# ioat91sam3s2 register map
Registers are 32-bit, access not given, no defined reset value unless marked. A register's access mark holds for its fields unless they carry their own. Addresses are absolute; registers are grouped by the start of their names; [hi:lo] are bit positions; {n}, {i} and the like mark numbered series; 'fields as' and 'values as' point back to an identical list.

## ACC
0x40040000 ACC_CR
  [0] SWRST
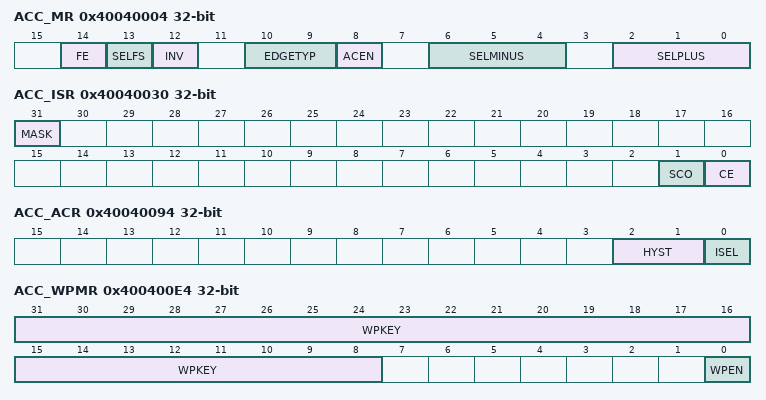
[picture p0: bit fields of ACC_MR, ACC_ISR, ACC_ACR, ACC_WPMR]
0x40040004 ACC_MR
  [14] FE, [13] SELFS, [12] INV, [10:9] EDGETYP, [8] ACEN, [6:4] SELMINUS, [2:0] SELPLUS
0x40040024 ACC_IER
  [0] CE
0x40040028 ACC_IDR
  [0] CE
0x4004002C ACC_IMR
  [0] CE
0x40040030 ACC_ISR
  [31] MASK, [1] SCO, [0] CE
0x40040094 ACC_ACR
  [2:1] HYST, [0] ISEL
0x400400E4 ACC_WPMR
  [31:8] WPKEY, [0] WPEN
0x400400E8 ACC_WPSR
  [0] WPROTERR

## CRCCU
0x40044000 CRCCU_DSCR
  [31:9] DSCR
0x40044008 CRCCU_DMA_EN
  [0] DMAEN
0x4004400C CRCCU_DMA_DIS
  [0] DMADIS
0x40044010 CRCCU_DMA_SR
  [0] DMASR
0x40044014 CRCCU_DMA_IER
  [0] DMAIER
0x40044018 CRCCU_DMA_IDR
  [0] DMAIDR
0x4004401C CRCCU_DMA_IMR
  [0] DMAIMR
0x40044020 CRCCU_DMA_ISR
  [0] DMAISR
0x40044034 CRCCU_CR
  [0] RESET
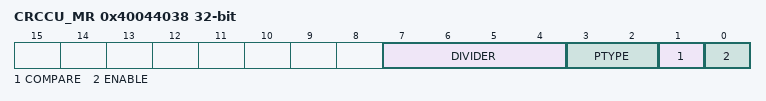
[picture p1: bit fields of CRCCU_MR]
0x40044038 CRCCU_MR
  [7:4] DIVIDER, [3:2] PTYPE, [1] COMPARE, [0] ENABLE
0x4004403C CRCCU_SR
  [31:0] CRC
0x40044040 CRCCU_IER
  [0] ERRIER
0x40044044 CRCCU_IDR
  [0] ERRIDR
0x40044048 CRCCU_IMR
  [0] ERRIMR
0x4004404C CRCCU_ISR
  [0] ERRISR

## SMC
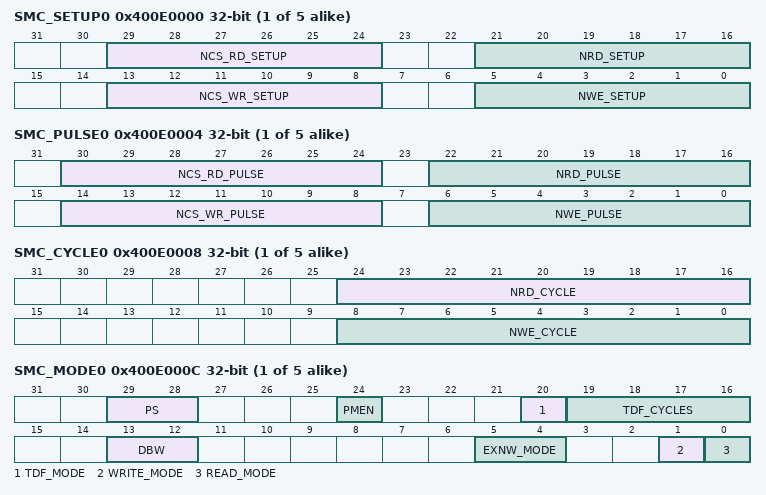
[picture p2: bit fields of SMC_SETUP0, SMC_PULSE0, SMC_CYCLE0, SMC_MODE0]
{0x400E0000+0x10*i} SMC_SETUP{i} (i=0..4)
  [29:24] NCS_RD_SETUP, [21:16] NRD_SETUP, [13:8] NCS_WR_SETUP, [5:0] NWE_SETUP
{0x400E0004+0x10*i} SMC_PULSE{i} (i=0..4)
  [30:24] NCS_RD_PULSE, [22:16] NRD_PULSE, [14:8] NCS_WR_PULSE, [6:0] NWE_PULSE
{0x400E0008+0x10*i} SMC_CYCLE{i} (i=0..4)
  [24:16] NRD_CYCLE, [8:0] NWE_CYCLE
{0x400E000C+0x10*i} SMC_MODE{i} (i=0..4)
  [29:28] PS, [24] PMEN, [20] TDF_MODE, [19:16] TDF_CYCLES, [13:12] DBW, [5:4] EXNW_MODE, [1] WRITE_MODE, [0] READ_MODE
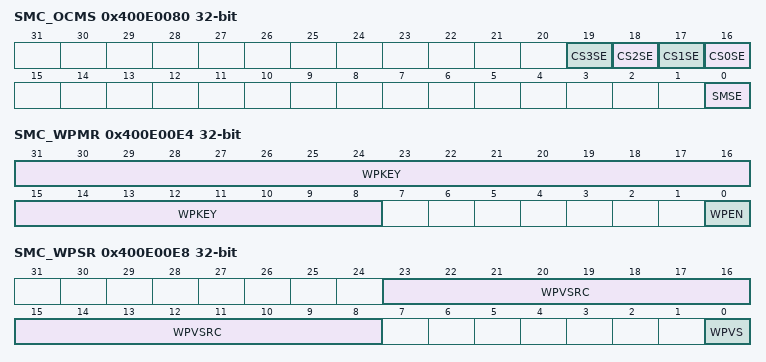
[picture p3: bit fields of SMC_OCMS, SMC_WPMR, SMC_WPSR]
0x400E0080 SMC_OCMS
  [n+16] CS{n}SE (n=0..3), [0] SMSE
0x400E0084 SMC_KEY1
0x400E0088 SMC_KEY2
0x400E00E4 SMC_WPMR
  [31:8] WPKEY, [0] WPEN
0x400E00E8 SMC_WPSR
  [23:8] WPVSRC, [0] WPVS

## MATRIX
0x400E0200 MATRIX_MCFG_{i} (i=0..3)
  [2:0] ULBT
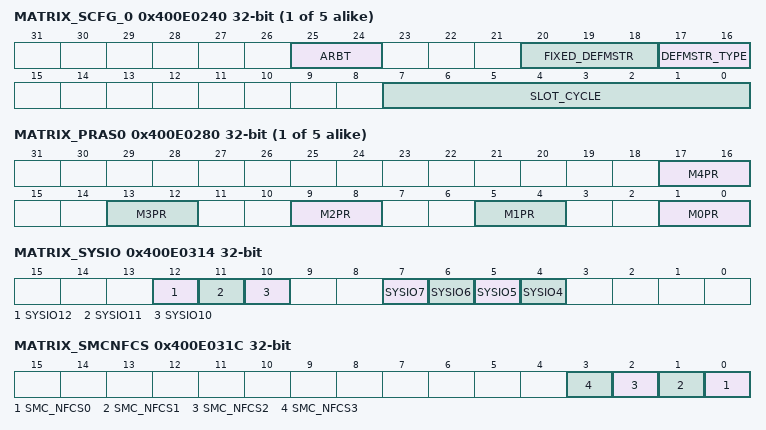
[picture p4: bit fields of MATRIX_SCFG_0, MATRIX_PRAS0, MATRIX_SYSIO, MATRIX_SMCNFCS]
0x400E0240 MATRIX_SCFG_{i} (i=0..4)
  [25:24] ARBT, [20:18] FIXED_DEFMSTR, [17:16] DEFMSTR_TYPE, [7:0] SLOT_CYCLE
{0x400E0280+8i} MATRIX_PRAS{i} (i=0..4)
  [4n+1:4n] M{n}PR (n=0..4)
0x400E0314 MATRIX_SYSIO
  [12] SYSIO12, [11] SYSIO11, [10] SYSIO10, [n] SYSIO{n} (n=4..7)
0x400E031C MATRIX_SMCNFCS
  [n] SMC_NFCS{n} (n=0..3)
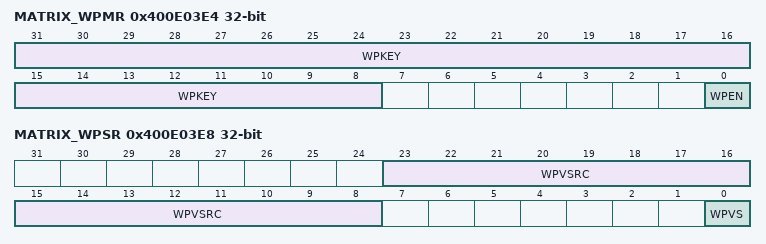
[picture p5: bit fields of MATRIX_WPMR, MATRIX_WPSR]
0x400E03E4 MATRIX_WPMR
  [31:8] WPKEY, [0] WPEN
0x400E03E8 MATRIX_WPSR
  [23:8] WPVSRC, [0] WPVS

## PMC
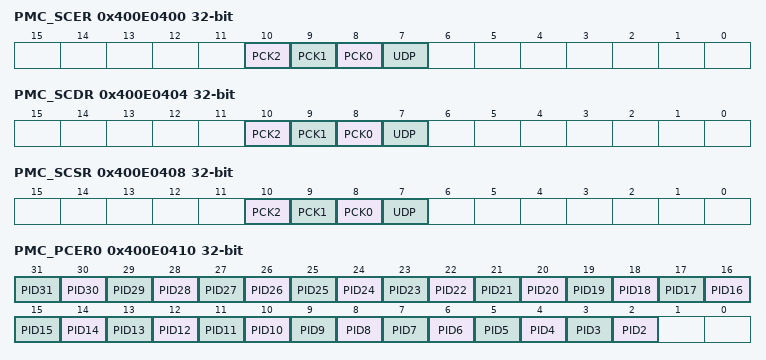
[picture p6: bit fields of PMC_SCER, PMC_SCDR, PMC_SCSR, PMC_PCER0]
0x400E0400 PMC_SCER
  [10] PCK2, [9] PCK1, [8] PCK0, [7] UDP
0x400E0404 PMC_SCDR
  [10] PCK2, [9] PCK1, [8] PCK0, [7] UDP
0x400E0408 PMC_SCSR
  [10] PCK2, [9] PCK1, [8] PCK0, [7] UDP
0x400E0410 PMC_PCER0
  [n] PID{n} (n=2..31)
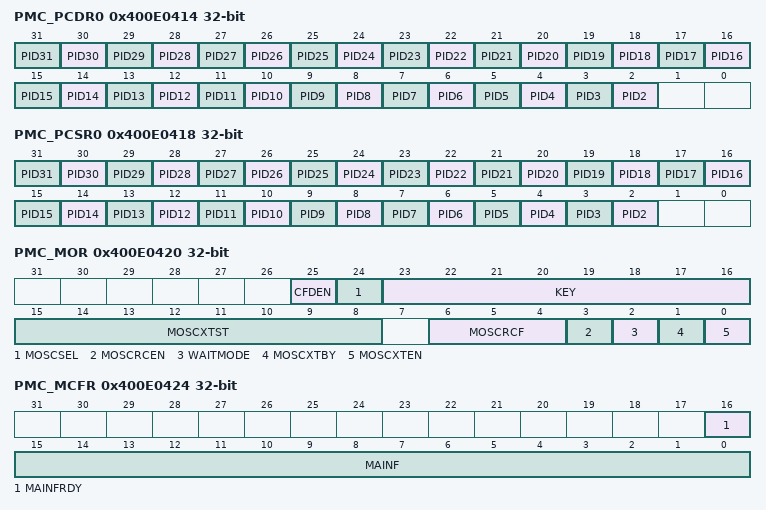
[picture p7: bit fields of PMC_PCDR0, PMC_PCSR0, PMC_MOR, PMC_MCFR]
0x400E0414 PMC_PCDR0
  [n] PID{n} (n=2..31)
0x400E0418 PMC_PCSR0
  [n] PID{n} (n=2..31)
0x400E0420 PMC_MOR
  [25] CFDEN, [24] MOSCSEL, [23:16] KEY, [15:8] MOSCXTST, [6:4] MOSCRCF, [3] MOSCRCEN, [2] WAITMODE, [1] MOSCXTBY, [0] MOSCXTEN
0x400E0424 PMC_MCFR
  [16] MAINFRDY, [15:0] MAINF
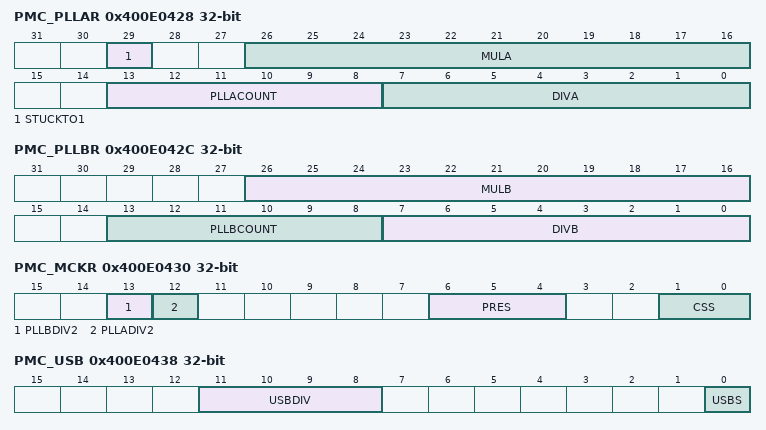
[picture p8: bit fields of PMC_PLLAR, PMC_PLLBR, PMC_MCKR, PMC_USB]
0x400E0428 PMC_PLLAR
  [29] STUCKTO1, [26:16] MULA, [13:8] PLLACOUNT, [7:0] DIVA
0x400E042C PMC_PLLBR
  [26:16] MULB, [13:8] PLLBCOUNT, [7:0] DIVB
0x400E0430 PMC_MCKR
  [13] PLLBDIV2, [12] PLLADIV2, [6:4] PRES, [1:0] CSS
0x400E0438 PMC_USB
  [11:8] USBDIV, [0] USBS
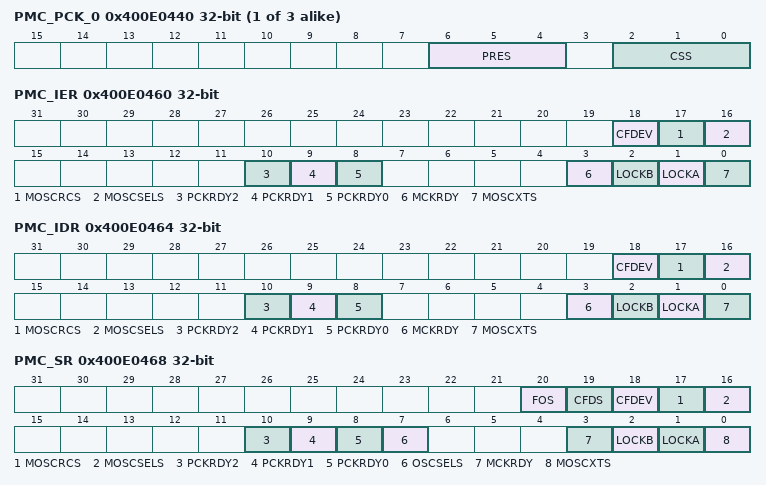
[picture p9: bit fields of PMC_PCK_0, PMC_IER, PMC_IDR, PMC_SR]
0x400E0440 PMC_PCK_{i} (i=0..2)
  [6:4] PRES, [2:0] CSS
0x400E0460 PMC_IER
  [18] CFDEV, [17] MOSCRCS, [16] MOSCSELS, [10] PCKRDY2, [9] PCKRDY1, [8] PCKRDY0, [3] MCKRDY, [2] LOCKB, [1] LOCKA, [0] MOSCXTS
0x400E0464 PMC_IDR
  fields as PMC_IER
0x400E0468 PMC_SR
  [20] FOS, [19] CFDS, [18] CFDEV, [17] MOSCRCS, [16] MOSCSELS, [10] PCKRDY2, [9] PCKRDY1, [8] PCKRDY0, [7] OSCSELS, [3] MCKRDY, [2] LOCKB, [1] LOCKA, [0] MOSCXTS
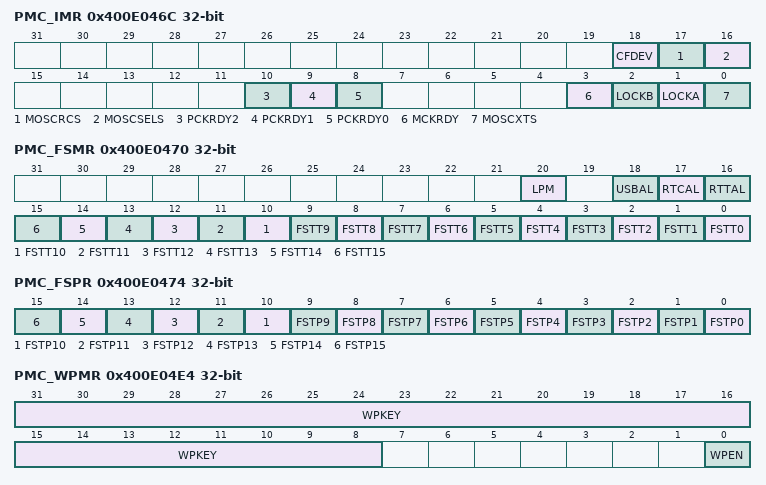
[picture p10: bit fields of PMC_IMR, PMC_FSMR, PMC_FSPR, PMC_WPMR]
0x400E046C PMC_IMR
  fields as PMC_IER
0x400E0470 PMC_FSMR
  [20] LPM, [18] USBAL, [17] RTCAL, [16] RTTAL, [n] FSTT{n} (n=0..15)
0x400E0474 PMC_FSPR
  [n] FSTP{n} (n=0..15)
0x400E0478 PMC_FOCR
  [0] FOCLR
0x400E04E4 PMC_WPMR
  [31:8] WPKEY, [0] WPEN
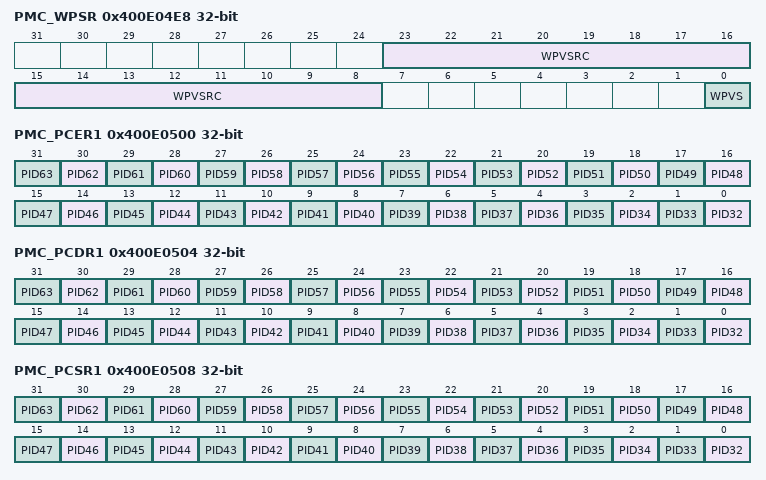
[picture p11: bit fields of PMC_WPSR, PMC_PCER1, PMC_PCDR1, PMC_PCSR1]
0x400E04E8 PMC_WPSR
  [23:8] WPVSRC, [0] WPVS
0x400E0500 PMC_PCER1
  [n-32] PID{n} (n=32..63)
0x400E0504 PMC_PCDR1
  [n-32] PID{n} (n=32..63)
0x400E0508 PMC_PCSR1
  [n-32] PID{n} (n=32..63)
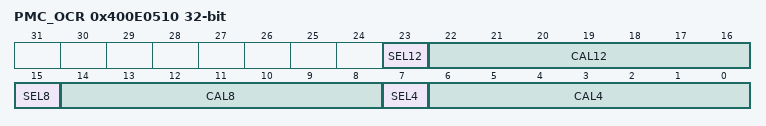
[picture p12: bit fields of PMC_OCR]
0x400E0510 PMC_OCR
  [23] SEL12, [22:16] CAL12, [15] SEL8, [14:8] CAL8, [7] SEL4, [6:0] CAL4
